# IMC300A register map
Vendor: Infineon; File version: 1.0.0
CPU: CM0 r0p0, little endian, no MPU, no FPU, 2 interrupt priority bits
Registers are 32-bit, read-write, reset 0x0 unless marked. A register's access mark holds for its fields unless they carry their own. Offsets are from the block's base; [hi:lo] are bit positions; {n}, {i} and the like mark numbered series; 'fields as' and 'values as' point back to an identical list.

## DAC — SD-DAC
Base 0x50030000
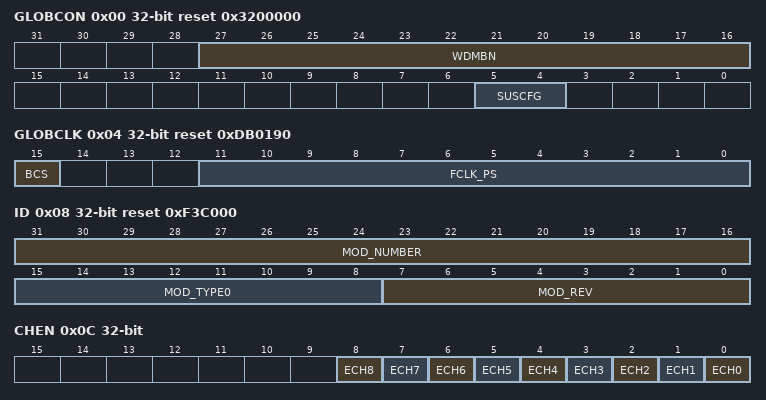
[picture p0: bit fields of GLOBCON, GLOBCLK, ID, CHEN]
0x00 GLOBCON reset 0x3200000 — Global Control
  [27:16] WDMBN — Watchdog Maximum Bitnumber
  [5:4] SUSCFG — Suspend Mode Configuration
    0=Suspend request is ignored and the module cannot get suspended; 1=Freeze channels and output level; 2=Freeze channels, but outputs go to passive level
0x04 GLOBCLK reset 0xDB0190 — Global Clock
  [15] BCS — Bit-Clock Selector
    0=Normal Mode: DAC_bclk is generated from DAC_fclk by a division of 4; 1=Fast Mode: DAC_bclk is the same as DAC_fclk
  [11:0] FCLK_PS — Fast Clock Prescaler Factor
    0=No clock; 1=Divide by 1; 0xFFF=Divide by 4095
0x08 ID ro reset 0xF3C000 (reset mask 0xFFFFFF00) — Module Identification
  [31:16] MOD_NUMBER — Module Number Value
  [15:8] MOD_TYPE0 — Module Type
  [7:0] MOD_REV — Module Revision Number
0x0C CHEN — Channel Enable
  [all] fields
    0=Channel is disabled, the output level is passive; 1=Channel is enabled
  [n] ECH{n} (n=0..8) — Channel {n} Enable
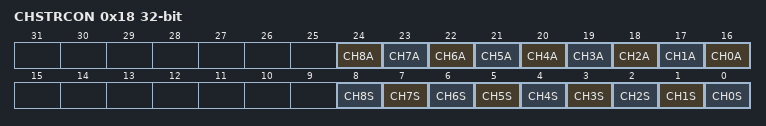
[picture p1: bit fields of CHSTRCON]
0x18 CHSTRCON access per field — Channel Shadow Transfer
  [n+16] CH{n}A wo (n=0..8) — Channel {n} Linear Walk Abort
    0=No action; 1=Abort linear walk
  [n] CH{n}S rw (n=0..8) — Channel {n} Shadow Transfer
    0=No action; 1=Initiate channel {n} target intensity shadow transfer

## DAC_CH0 — SD-DAC
Base 0x5003003C
Same registers: DAC_CH{n} {0x5003003C+0x14*n} (n=1..8)
0x00 DATAS — Channel Data Shadow
  [11:0] TCHDATA — Target Channel Data Value
0x04 DATA ro — Channel Data
  [11:0] CHDATA — Channel Data Value
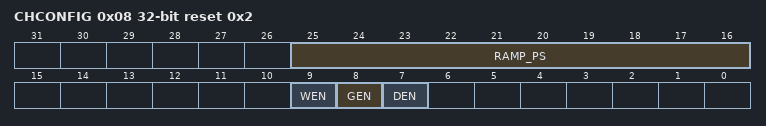
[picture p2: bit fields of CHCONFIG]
0x08 CHCONFIG reset 0x2 — Channel Configuration
  [25:16] RAMP_PS — Ramp Clock Prescaler
  [9] WEN — Flicker Watchdog Enable
    0=Disable flicker watchdog; 1=Enable flicker watchdog
  [8] GEN — Gating Enable
    0=Gating function is disabled, the input signal (DAC.INy) has no effect; 1=Gating function is enabled, the output gating signal is DAC.INy
  [7] DEN — Data Value Enable
    0=Channel data values are irgnored; 1=Channel data values are processed

## PORT0
Base 0x40040000
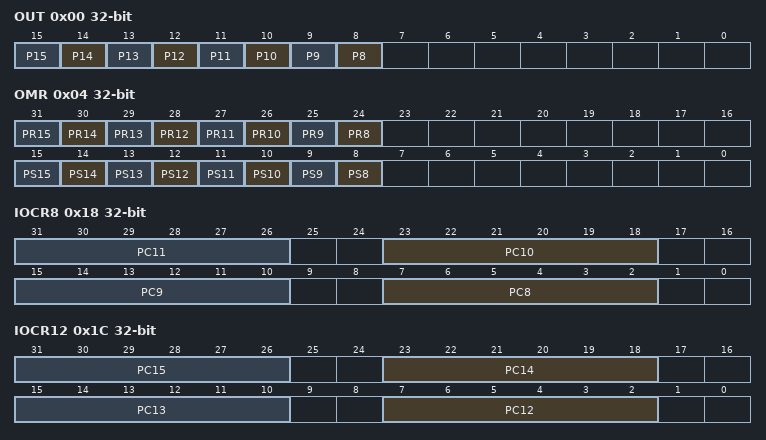
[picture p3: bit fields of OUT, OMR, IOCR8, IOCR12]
0x00 OUT — Port 0 Output Register
  [all] fields
    0=The output level of P0.x is 0; 1=The output level of P0.x is 1
  [n] P{n} (n=8..15) — Port 0 Output Bit {n}
0x04 OMR wo — Port 0 Output Modification Register
  [n+16] PR{n} (n=8..15) — Port 0 Reset Bit {n}
  [n] PS{n} (n=8..15) — Port 0 Set Bit {n}
0x18 IOCR8 — Port 0 Input/Output Control Register 8
  [all] fields
    0=Input - No internal pull device active; 1=Input - Internal pull-down device active; 2=Input - Internal pull-up device active; 3=Input - No internal pull device, Pn_OUTx = input value; 4=Input inverted - No internal pull device active; 5=Input inverted - Internal pull-down device active; 6=Input inverted - Internal pull-up device active; 7=Input inverted - No internal pull device, Pn_OUTx = input value; 32=Output Push-Pull - General-purpose output; {v}=Output Push-Pull - Alternate output function {v-32} (v=33..41); 48=Output Open Drain - General-purpose output; {v}=Output Open Drain - Alternate output function {v-48} (v=49..57)
  [8n-57:8n-62] PC{n} (n=8..11) — Port Control for Port 0 Pin {n}
0x1C IOCR12 — Port 0 Input/Output Control Register 12
  [all] fields
    values as the fields of IOCR8
  [8n-89:8n-94] PC{n} (n=12..15) — Port Control for Port 0 Pin {n}
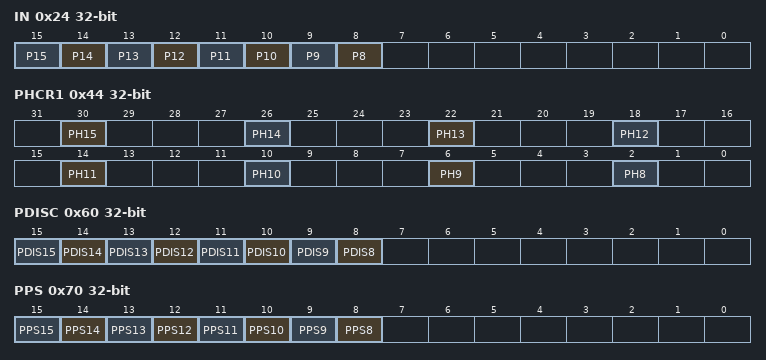
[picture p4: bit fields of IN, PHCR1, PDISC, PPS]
0x24 IN ro (reset mask 0xFFFF0000) — Port 0 Input Register
  [all] fields
    0=The input level of P0.x is 0; 1=The input level of P0.x is 1
  [n] P{n} (n=8..15) — Port 0 Input Bit {n}
0x44 PHCR1 — Port 0 Pad Hysteresis Control Register 1
  [30] PH15 — Pad Hysteresis for P0.15
  [26] PH14 — Pad Hysteresis for P0.14
  [22] PH13 — Pad Hysteresis for P0.13
  [18] PH12 — Pad Hysteresis for P0.12
  [14] PH11 — Pad Hysteresis for P0.11
  [10] PH10 — Pad Hysteresis for P0.10
  [6] PH9 — Pad Hysteresis for P0.9
  [2] PH8 — Pad Hysteresis for P0.8
0x60 PDISC ro (reset mask 0xFFFF0000) — Port 0 Pin Function Decision Control Register
  [all] fields
    0=Pad P0.x is enabled; 1=Pad P0.x is disabled
  [n] PDIS{n} (n=8..15) — Pad Disable for Port 0 Pin {n}
0x70 PPS — Port 0 Pin Power Save Register
  [all] fields
    0=Pin Power Save of P0.x is disabled; 1=Pin Power Save of P0.x is enabled
  [n] PPS{n} (n=8..15) — Port 0 Pin Power Save Bit {n}
